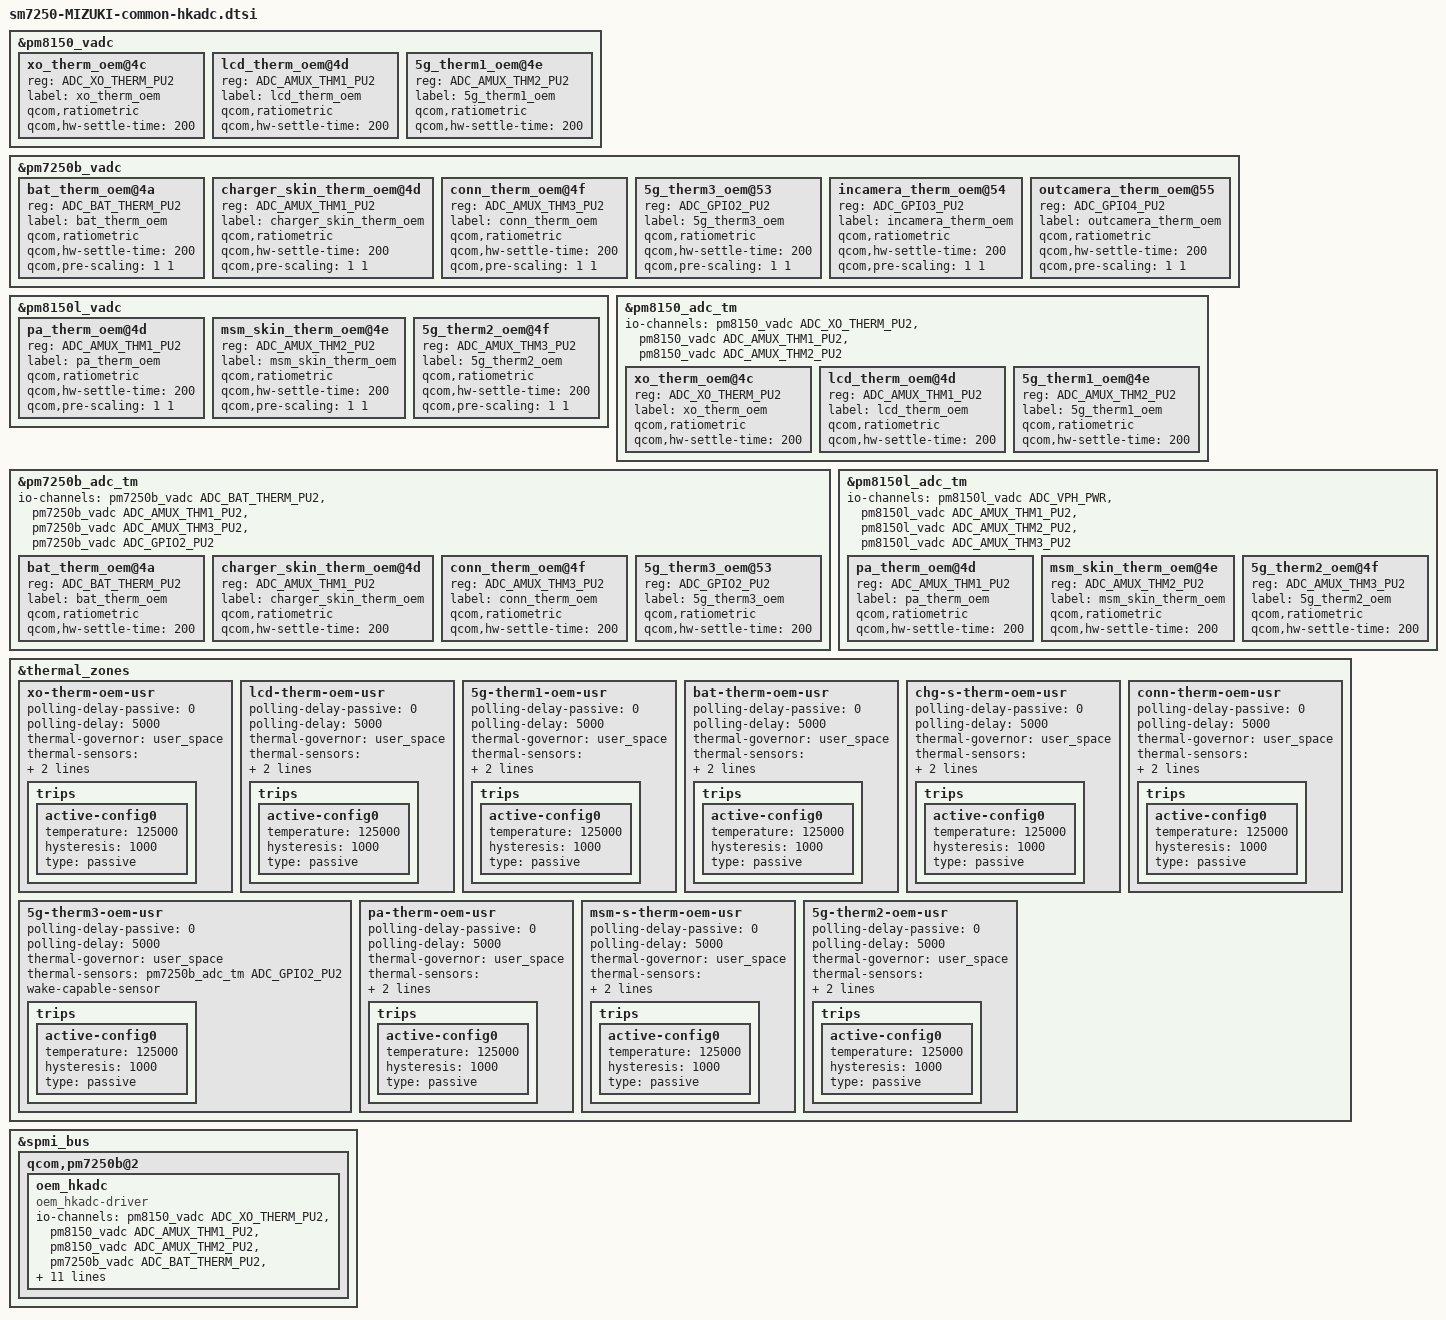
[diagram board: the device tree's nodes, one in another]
/*
 * This software is contributed or developed by KYOCERA Corporation.
 * (C) 2020 KYOCERA Corporation
 *
 * This program is free software; you can redistribute it and/or modify
 * it under the terms of the GNU General Public License version 2 and
 * only version 2 as published by the Free Software Foundation.
 *
 * This program is distributed in the hope that it will be useful,
 * but WITHOUT ANY WARRANTY; without even the implied warranty of
 * MERCHANTABILITY or FITNESS FOR A PARTICULAR PURPOSE.  See the
 * GNU General Public License for more details.
 */


&pm8150_vadc {
	/delete-node/ xo_therm@4c;
	xo_therm_oem@4c {
		reg = <ADC_XO_THERM_PU2>;
		label = "xo_therm_oem";
		qcom,ratiometric;
		qcom,hw-settle-time = <200>;
	};

	/delete-node/ pa_therm1@4d;
	lcd_therm_oem@4d {
		reg = <ADC_AMUX_THM1_PU2>;
		label = "lcd_therm_oem";
		qcom,ratiometric;
		qcom,hw-settle-time = <200>;
	};

	/delete-node/ bmr_e_therm@4e;
	5g_therm1_oem@4e {
		reg = <ADC_AMUX_THM2_PU2>;
		label = "5g_therm1_oem";
		qcom,ratiometric;
		qcom,hw-settle-time = <200>;
	};
};

&pm7250b_vadc {
	/delete-node/ bat_therm@4a;
	bat_therm_oem@4a {
		reg = <ADC_BAT_THERM_PU2>;
		label = "bat_therm_oem";
		qcom,ratiometric;
		qcom,hw-settle-time = <200>;
		qcom,pre-scaling = <1 1>;
	};

	/delete-node/ charger_skin_therm@4d;
	charger_skin_therm_oem@4d {
		reg = <ADC_AMUX_THM1_PU2>;
		label = "charger_skin_therm_oem";
		qcom,ratiometric;
		qcom,hw-settle-time = <200>;
		qcom,pre-scaling = <1 1>;
	};

	/delete-node/ conn_therm@4f;
	conn_therm_oem@4f {
		reg = <ADC_AMUX_THM3_PU2>;
		label = "conn_therm_oem";
		qcom,ratiometric;
		qcom,hw-settle-time = <200>;
		qcom,pre-scaling = <1 1>;
	};

	/delete-node/ bmr_w_therm@53;
	5g_therm3_oem@53 {
		reg = <ADC_GPIO2_PU2>;
		label = "5g_therm3_oem";
		qcom,ratiometric;
		qcom,hw-settle-time = <200>;
		qcom,pre-scaling = <1 1>;
	};

	incamera_therm_oem@54 {
		reg = <ADC_GPIO3_PU2>;
		label = "incamera_therm_oem";
		qcom,ratiometric;
		qcom,hw-settle-time = <200>;
		qcom,pre-scaling = <1 1>;
	};

	/delete-node/ camera_flash_therm@55;
	outcamera_therm_oem@55 {
		reg = <ADC_GPIO4_PU2>;
		label = "outcamera_therm_oem";
		qcom,ratiometric;
		qcom,hw-settle-time = <200>;
		qcom,pre-scaling = <1 1>;
	};
};

&pm8150l_vadc {
	/delete-node/ pa_therm2@4d;
	pa_therm_oem@4d {
		reg = <ADC_AMUX_THM1_PU2>;
		label = "pa_therm_oem";
		qcom,ratiometric;
		qcom,hw-settle-time = <200>;
		qcom,pre-scaling = <1 1>;
	};

	/delete-node/ msm_skin_therm@4e;
	msm_skin_therm_oem@4e {
		reg = <ADC_AMUX_THM2_PU2>;
		label = "msm_skin_therm_oem";
		qcom,ratiometric;
		qcom,hw-settle-time = <200>;
		qcom,pre-scaling = <1 1>;
	};

	/delete-node/ bmr_n_therm@4f;
	5g_therm2_oem@4f {
		reg = <ADC_AMUX_THM3_PU2>;
		label = "5g_therm2_oem";
		qcom,ratiometric;
		qcom,hw-settle-time = <200>;
		qcom,pre-scaling = <1 1>;
	};
};

&pm8150_adc_tm {
	io-channels = <&pm8150_vadc ADC_XO_THERM_PU2>,
			<&pm8150_vadc ADC_AMUX_THM1_PU2>,
			<&pm8150_vadc ADC_AMUX_THM2_PU2>;

	/* Channel nodes */
	/delete-node/ xo_therm@4c;
	xo_therm_oem@4c {
		reg = <ADC_XO_THERM_PU2>;
		label = "xo_therm_oem";
		qcom,ratiometric;
		qcom,hw-settle-time = <200>;
	};

	/delete-node/ pa_therm1@4d;
	lcd_therm_oem@4d {
		reg = <ADC_AMUX_THM1_PU2>;
		label = "lcd_therm_oem";
		qcom,ratiometric;
		qcom,hw-settle-time = <200>;
	};

	/delete-node/ bmr_e_therm@4e;
	5g_therm1_oem@4e {
		reg = <ADC_AMUX_THM2_PU2>;
		label = "5g_therm1_oem";
		qcom,ratiometric;
		qcom,hw-settle-time = <200>;
	};
};

&pm7250b_adc_tm {
	io-channels = <&pm7250b_vadc ADC_BAT_THERM_PU2>,
			<&pm7250b_vadc ADC_AMUX_THM1_PU2>,
			<&pm7250b_vadc ADC_AMUX_THM3_PU2>,
			<&pm7250b_vadc ADC_GPIO2_PU2>;

	/* Channel nodes */
	/delete-node/ camera_flash_therm@55;

	/delete-node/ bat_therm@4a;
	bat_therm_oem@4a {
		reg = <ADC_BAT_THERM_PU2>;
		label = "bat_therm_oem";
		qcom,ratiometric;
		qcom,hw-settle-time = <200>;
	};

	/delete-node/ charger_skin_therm@4d;
	charger_skin_therm_oem@4d {
		reg = <ADC_AMUX_THM1_PU2>;
		label = "charger_skin_therm_oem";
		qcom,ratiometric;
		qcom,hw-settle-time = <200>;
	};

	/delete-node/ conn_therm@4f;
	conn_therm_oem@4f {
		reg = <ADC_AMUX_THM3_PU2>;
		label = "conn_therm_oem";
		qcom,ratiometric;
		qcom,hw-settle-time = <200>;
	};

	/delete-node/ bmr_w_therm@53;
	5g_therm3_oem@53 {
		reg = <ADC_GPIO2_PU2>;
		label = "5g_therm3_oem";
		qcom,ratiometric;
		qcom,hw-settle-time = <200>;
	};
};

&pm8150l_adc_tm {
	io-channels = <&pm8150l_vadc ADC_VPH_PWR>,
			<&pm8150l_vadc ADC_AMUX_THM1_PU2>,
			<&pm8150l_vadc ADC_AMUX_THM2_PU2>,
			<&pm8150l_vadc ADC_AMUX_THM3_PU2>;

	/* Channel nodes */
	/delete-node/ pa_therm2@4d;
	pa_therm_oem@4d {
		reg = <ADC_AMUX_THM1_PU2>;
		label = "pa_therm_oem";
		qcom,ratiometric;
		qcom,hw-settle-time = <200>;
	};

	/delete-node/ msm_skin_therm@4e;
	msm_skin_therm_oem@4e {
		reg = <ADC_AMUX_THM2_PU2>;
		label = "msm_skin_therm_oem";
		qcom,ratiometric;
		qcom,hw-settle-time = <200>;
	};

	/delete-node/ bmr_n_therm@4f;
	5g_therm2_oem@4f {
		reg = <ADC_AMUX_THM3_PU2>;
		label = "5g_therm2_oem";
		qcom,ratiometric;
		qcom,hw-settle-time = <200>;
	};
};

&thermal_zones {
	/delete-node/ xo-therm-usr;
	xo-therm-oem-usr {
		polling-delay-passive = <0>;
		polling-delay = <5000>;
		thermal-governor = "user_space";
		thermal-sensors = <&pm8150_adc_tm ADC_XO_THERM_PU2>;
		wake-capable-sensor;
		trips {
			active-config0 {
				temperature = <125000>;
				hysteresis = <1000>;
				type = "passive";
			};
		};
	};

	/delete-node/ pa-therm1-usr;
	lcd-therm-oem-usr {
		polling-delay-passive = <0>;
		polling-delay = <5000>;
		thermal-governor = "user_space";
		thermal-sensors = <&pm8150_adc_tm ADC_AMUX_THM1_PU2>;
		wake-capable-sensor;
		trips {
			active-config0 {
				temperature = <125000>;
				hysteresis = <1000>;
				type = "passive";
			};
		};
	};

	/delete-node/ mmw-pa3-usr;
	5g-therm1-oem-usr {
		polling-delay-passive = <0>;
		polling-delay = <5000>;
		thermal-governor = "user_space";
		thermal-sensors = <&pm8150_adc_tm ADC_AMUX_THM2_PU2>;
		wake-capable-sensor;
		trips {
			active-config0 {
				temperature = <125000>;
				hysteresis = <1000>;
				type = "passive";
			};
		};
	};

	bat-therm-oem-usr {
		polling-delay-passive = <0>;
		polling-delay = <5000>;
		thermal-governor = "user_space";
		thermal-sensors = <&pm7250b_adc_tm ADC_BAT_THERM_PU2>;
		wake-capable-sensor;
		trips {
			active-config0 {
				temperature = <125000>;
				hysteresis = <1000>;
				type = "passive";
			};
		};
	};

	/delete-node/ charger-therm-usr;
	chg-s-therm-oem-usr {
		polling-delay-passive = <0>;
		polling-delay = <5000>;
		thermal-governor = "user_space";
		thermal-sensors = <&pm7250b_adc_tm ADC_AMUX_THM1_PU2>;
		wake-capable-sensor;
		trips {
			active-config0 {
				temperature = <125000>;
				hysteresis = <1000>;
				type = "passive";
			};
		};
	};

	conn-therm-oem-usr {
		polling-delay-passive = <0>;
		polling-delay = <5000>;
		thermal-governor = "user_space";
		thermal-sensors = <&pm7250b_adc_tm ADC_AMUX_THM3_PU2>;
		wake-capable-sensor;
		trips {
			active-config0 {
				temperature = <125000>;
				hysteresis = <1000>;
				type = "passive";
			};
		};
	};

	/delete-node/ mmw-pa2-usr;
	5g-therm3-oem-usr {
		polling-delay-passive = <0>;
		polling-delay = <5000>;
		thermal-governor = "user_space";
		thermal-sensors = <&pm7250b_adc_tm ADC_GPIO2_PU2>;
		wake-capable-sensor;
		trips {
			active-config0 {
				temperature = <125000>;
				hysteresis = <1000>;
				type = "passive";
			};
		};
	};

	/delete-node/ pa-therm2-usr;
	pa-therm-oem-usr {
		polling-delay-passive = <0>;
		polling-delay = <5000>;
		thermal-governor = "user_space";
		thermal-sensors = <&pm8150l_adc_tm ADC_AMUX_THM1_PU2>;
		wake-capable-sensor;
		trips {
			active-config0 {
				temperature = <125000>;
				hysteresis = <1000>;
				type = "passive";
			};
		};
	};

	/delete-node/ msm-s-therm-usr;
	msm-s-therm-oem-usr {
		polling-delay-passive = <0>;
		polling-delay = <5000>;
		thermal-governor = "user_space";
		thermal-sensors = <&pm8150l_adc_tm ADC_AMUX_THM2_PU2>;
		wake-capable-sensor;
		trips {
			active-config0 {
				temperature = <125000>;
				hysteresis = <1000>;
				type = "passive";
			};
		};
	};

	/delete-node/ mmw-pa1-usr;
	5g-therm2-oem-usr {
		polling-delay-passive = <0>;
		polling-delay = <5000>;
		thermal-governor = "user_space";
		thermal-sensors = <&pm8150l_adc_tm ADC_AMUX_THM3_PU2>;
		wake-capable-sensor;
		trips {
			active-config0 {
				temperature = <125000>;
				hysteresis = <1000>;
				type = "passive";
			};
		};
	};
};

&spmi_bus {
	qcom,pm7250b@2 {
		oem_hkadc {
			compatible = "oem_hkadc-driver";
			io-channels = <&pm8150_vadc ADC_XO_THERM_PU2>,
			              <&pm8150_vadc ADC_AMUX_THM1_PU2>,
			              <&pm8150_vadc ADC_AMUX_THM2_PU2>,
			              <&pm7250b_vadc ADC_BAT_THERM_PU2>,
			              <&pm7250b_vadc ADC_AMUX_THM1_PU2>,
			              <&pm7250b_vadc ADC_AMUX_THM3_PU2>,
			              <&pm7250b_vadc ADC_GPIO2_PU2>,
			              <&pm7250b_vadc ADC_GPIO3_PU2>,
			              <&pm7250b_vadc ADC_GPIO4_PU2>,
			              <&pm8150l_vadc ADC_AMUX_THM1_PU2>,
			              <&pm8150l_vadc ADC_AMUX_THM2_PU2>,
			              <&pm8150l_vadc ADC_AMUX_THM3_PU2>;
			io-channel-names = "xo-therm",
			                   "lcd-therm",
			                   "5g-therm-1",
			                   "bat-therm",
			                   "charger-skin-therm",
			                   "conn-therm",
			                   "5g-therm-3",
			                   "incamera-therm",
			                   "outcamera-therm",
			                   "pa-therm",
			                   "skin-therm",
			                   "5g-therm-2";
			oem,monitor-time-ms = <5000>;
			oem,resume-mon-time-ms = <1000>;
			oem,camera-therm-diasble;
		};
	};
};
